# EFM32GG995F1024 register map
File version: 5.4.0
Silicon Labs EFM32GG995F1024 Cortex-M MCU
Registers are 32-bit, read-write, reset 0x0 unless marked. A register's access mark holds for its fields unless they carry their own. Offsets are from the block's base; lines under a group give offsets from that group; [hi:lo] are bit positions; {n}, {i} and the like mark numbered series; 'fields as' and 'values as' point back to an identical list; <NAME> marks a mode.

## Memory map
0x40000000 VCMP size 0x400
0x40001000 ACMP0 size 0x400
0x40001400 ACMP1 size 0x400
0x40002000 ADC0 size 0x400
0x40004000 DAC0 size 0x400
0x40006000 GPIO size 0x1000
0x40008000 EBI size 0x400
0x4000A000 I2C0 size 0x400
0x4000A400 I2C1 size 0x400
0x4000C000 USART0 size 0x400
0x4000C400 USART1 size 0x400
0x4000C800 USART2 size 0x400
0x4000E000 UART0 size 0x400
0x4000E400 UART1 size 0x400
0x40010000 TIMER0 size 0x400
0x40010400 TIMER1 size 0x400
0x40010800 TIMER2 size 0x400
0x40010C00 TIMER3 size 0x400
0x40080000 RTC size 0x400
0x40081000 BURTC size 0x400
0x40082000 LETIMER0 size 0x400
0x40084000 LEUART0 size 0x400
0x40084400 LEUART1 size 0x400
0x40086000 PCNT0 size 0x400
0x40086400 PCNT1 size 0x400
0x40086800 PCNT2 size 0x400
0x40088000 WDOG size 0x400
0x4008A000 LCD size 0x400
0x4008C000 LESENSE size 0x400
0x400C0000 MSC size 0x400
0x400C2000 DMA size 0x2000
0x400C4000 USB blocks up to offset 0x3D000
0x400C6000 EMU size 0x400
0x400C8000 CMU size 0x400
0x400CA000 RMU size 0x400
0x400CC000 PRS size 0x400
0x400E0000 AES size 0x400
0xE0041000 ETM size 0x40000

## Interrupts
0 DMATEST (DMA)
1 GPIO_EVEN (GPIO)
2 TIMER0
3 USART0_RX (USART0)
4 USART0_TX (USART0)
5 USB
6 ACMP0 (ACMP0, ACMP1)
7 ADC0
8 DAC0
9 I2C0
10 I2C1
11 GPIO_ODD (GPIO)
12 TIMER1
13 TIMER2
14 TIMER3
15 USART1_RX (USART1)
16 USART1_TX (USART1)
17 LESENSE
18 USART2_RX (USART2)
19 USART2_TX (USART2)
20 UART0_RX (UART0)
21 UART0_TX (UART0)
22 UART1_RX (UART1)
23 UART1_TX (UART1)
24 LEUART0
25 LEUART1
26 LETIMER0
27 PCNT0
28 PCNT1
29 PCNT2
30 RTC
31 BURTC
32 CMU
33 VCMP
34 LCD
35 MSC
36 AES
37 EBI
38 EMU

## Further device data
name=Copyright 2017 Silicon Laboratories, Inc., flashBaseAddress=0x00000000, flashSize=0x00100000, flashAccessTypes=rx, sramBaseAddress=0x20000000, sramSize=0x00020000, sramAccessTypes=rwx

## AES
Base 0x400E0000
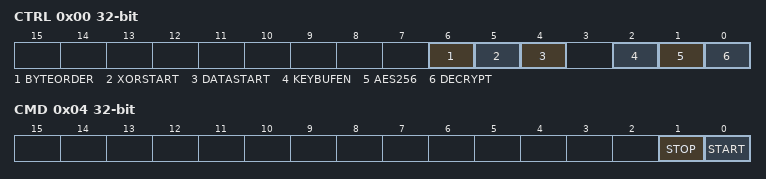
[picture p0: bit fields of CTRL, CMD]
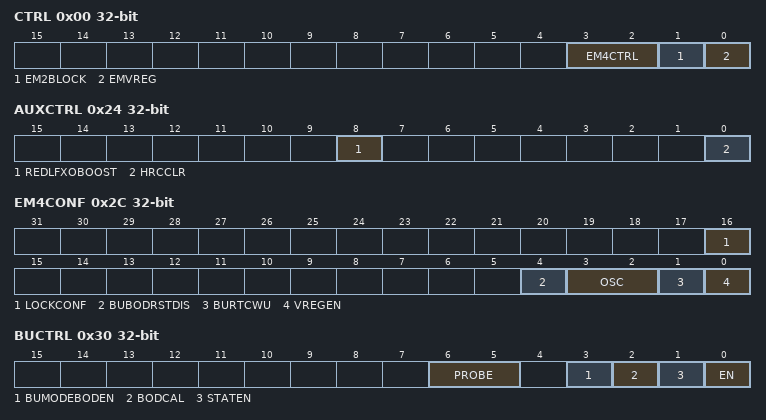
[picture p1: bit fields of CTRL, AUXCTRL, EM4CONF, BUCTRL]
0x00 CTRL — Control Register
  [6] BYTEORDER — Configure byte order in data and key registers
  [5] XORSTART — AES_XORDATA Write Start
  [4] DATASTART — AES_DATA Write Start
  [2] KEYBUFEN — Key Buffer Enable
  [1] AES256 — AES-256 Mode
  [0] DECRYPT — Decryption/Encryption Mode
0x04 CMD wo — Command Register
  [1] STOP — Encryption/Decryption Stop
  [0] START — Encryption/Decryption Start
0x08 STATUS ro
  [0] RUNNING — AES Running
0x0C IEN — Interrupt Enable Register
  [0] DONE — Encryption/Decryption Done Interrupt Enable
0x10 IF ro — Interrupt Flag Register
  [0] DONE — Encryption/Decryption Done Interrupt Flag
0x14 IFS wo — Interrupt Flag Set Register
  [0] DONE — Encryption/Decryption Done Interrupt Flag Set
0x18 IFC wo — Interrupt Flag Clear Register
  [0] DONE — Encryption/Decryption Done Interrupt Flag Clear
0x1C DATA read-has-side-effects
  [31:0] DATA — Data Access
0x20 XORDATA read-has-side-effects
  [31:0] XORDATA — XOR Data Access
0x30 KEYLA read-has-side-effects — KEY Low Register
  [31:0] KEYLA — Key Low Access A
0x34 KEYLB read-has-side-effects — KEY Low Register
  [31:0] KEYLB — Key Low Access B
0x38 KEYLC read-has-side-effects — KEY Low Register
  [31:0] KEYLC — Key Low Access C
0x3C KEYLD read-has-side-effects — KEY Low Register
  [31:0] KEYLD — Key Low Access D
0x40 KEYHA read-has-side-effects — KEY High Register
  [31:0] KEYHA — Key High Access A
0x44 KEYHB read-has-side-effects — KEY High Register
  [31:0] KEYHB — Key High Access B
0x48 KEYHC read-has-side-effects — KEY High Register
  [31:0] KEYHC — Key High Access C
0x4C KEYHD read-has-side-effects — KEY High Register
  [31:0] KEYHD — Key High Access D

## EMU
Base 0x400C6000
0x00 CTRL — Control Register
  [3:2] EM4CTRL — Energy Mode 4 Control
  [1] EM2BLOCK — Energy Mode 2 Block
  [0] EMVREG — Energy Mode Voltage Regulator Control
0x04 MEMCTRL — Memory Control Register
  [2:0] POWERDOWN — RAM block power-down
    4=BLK3 (Power down RAM block 3 (address range 0x20018000-0x2001FFFF).); 6=BLK23 (Power down RAM blocks 2-3 (address range 0x20010000-0x2001FFFF).); 7=BLK123 (Power down RAM blocks 1-3 (address range 0x20008000-0x2001FFFF).)
0x08 LOCK — Configuration Lock Register
  [15:0] LOCKKEY — Configuration Lock Key
    0=UNLOCKED; 1=LOCKED
0x24 AUXCTRL — Auxiliary Control Register
  [8] REDLFXOBOOST — Reduce LFXO Start-up Boost Current
  [0] HRCCLR — Hard Reset Cause Clear
0x2C EM4CONF — Energy mode 4 configuration register
  [16] LOCKCONF — EM4 configuration lock enable
  [4] BUBODRSTDIS — Disable reset from Backup BOD in EM4
  [3:2] OSC — Select EM4 duty oscillator
    0=ULFRCO (ULFRCO is available.); 1=LFRCO (LFRCO is available. Can only be set if LFRCO is running before EM4/backup entry.); 2=LFXO (LFXO is available. Can only be set if LFXO is available before EM4/backup entry.)
  [1] BURTCWU — Backup RTC EM4 wakeup enable
  [0] VREGEN — EM4 voltage regulator enable
0x30 BUCTRL — Backup Power configuration register
  [6:5] PROBE — Voltage probe select
    0=DISABLE (Disable voltage probe.); 1=VDDDREG (Connect probe to VDD_DREG.); 2=BUIN (Connect probe to BU_IN.); 3=BUOUT (Connect probe to BU_OUT.)
  [3] BUMODEBODEN — Enable brown out detection on BU_VIN when in backup mode
  [2] BODCAL — Enable BOD calibration mode
  [1] STATEN — Enable backup mode status export
  [0] EN — Enable backup mode
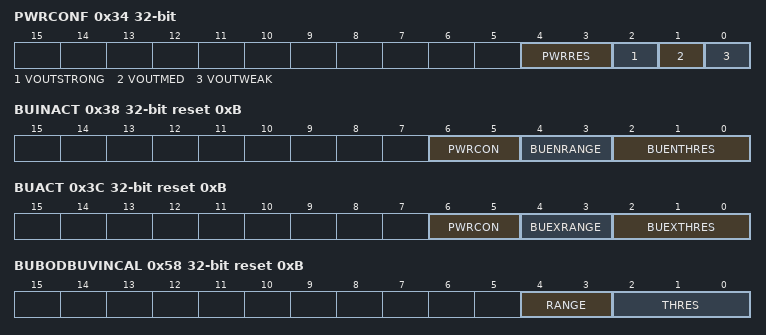
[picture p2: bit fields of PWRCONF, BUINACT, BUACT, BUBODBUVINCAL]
0x34 PWRCONF — Power connection configuration register
  [4:3] PWRRES — Power domain resistor select
    {v}=RES{v} (Main power and backup power connected with RES{v} series resistance.) (v=0..3)
  [2] VOUTSTRONG — BU_VOUT strong enable
  [1] VOUTMED — BU_VOUT medium enable
  [0] VOUTWEAK — BU_VOUT weak enable
0x38 BUINACT reset 0xB — Backup mode inactive configuration register
  [6:5] PWRCON — Power connection configuration when not in Backup mode
    0=NONE (No connection.); 1=BUMAIN (Main power and backup power are connected through a diode, allowing current to flow from backup power source to main power source, but not the other way.); 2=MAINBU (Main power and backup power are connected through a diode, allowing current to flow from main power source to backup power source, but not the other way.); 3=NODIODE (Main power and backup power are connected without diode.)
  [4:3] BUENRANGE — ""
  [2:0] BUENTHRES — ""
0x3C BUACT reset 0xB — Backup mode active configuration register
  [6:5] PWRCON — Power connection configuration when in Backup mode
    values as BUINACT.PWRCON
  [4:3] BUEXRANGE — ""
  [2:0] BUEXTHRES — ""
0x40 STATUS ro
  [0] BURDY — Backup mode ready
0x44 ROUTE reset 0x1 — I/O Routing Register
  [0] BUVINPEN — BU_VIN Pin Enable
0x48 IF ro — Interrupt Flag Register
  [0] BURDY — Backup functionality ready Interrupt Flag
0x4C IFS wo — Interrupt Flag Set Register
  [0] BURDY — Set Backup functionality ready Interrupt Flag
0x50 IFC wo — Interrupt Flag Clear Register
  [0] BURDY — Clear Backup functionality ready Interrupt Flag
0x54 IEN — Interrupt Enable Register
  [0] BURDY — Backup functionality ready Interrupt Enable
0x58 BUBODBUVINCAL reset 0xB — BU_VIN Backup BOD calibration
  [4:3] RANGE — ""
  [2:0] THRES — ""
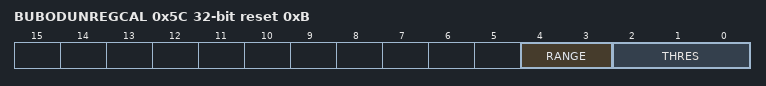
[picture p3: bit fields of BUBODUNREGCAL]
0x5C BUBODUNREGCAL reset 0xB — Unregulated power Backup BOD calibration
  [4:3] RANGE — ""
  [2:0] THRES — ""
